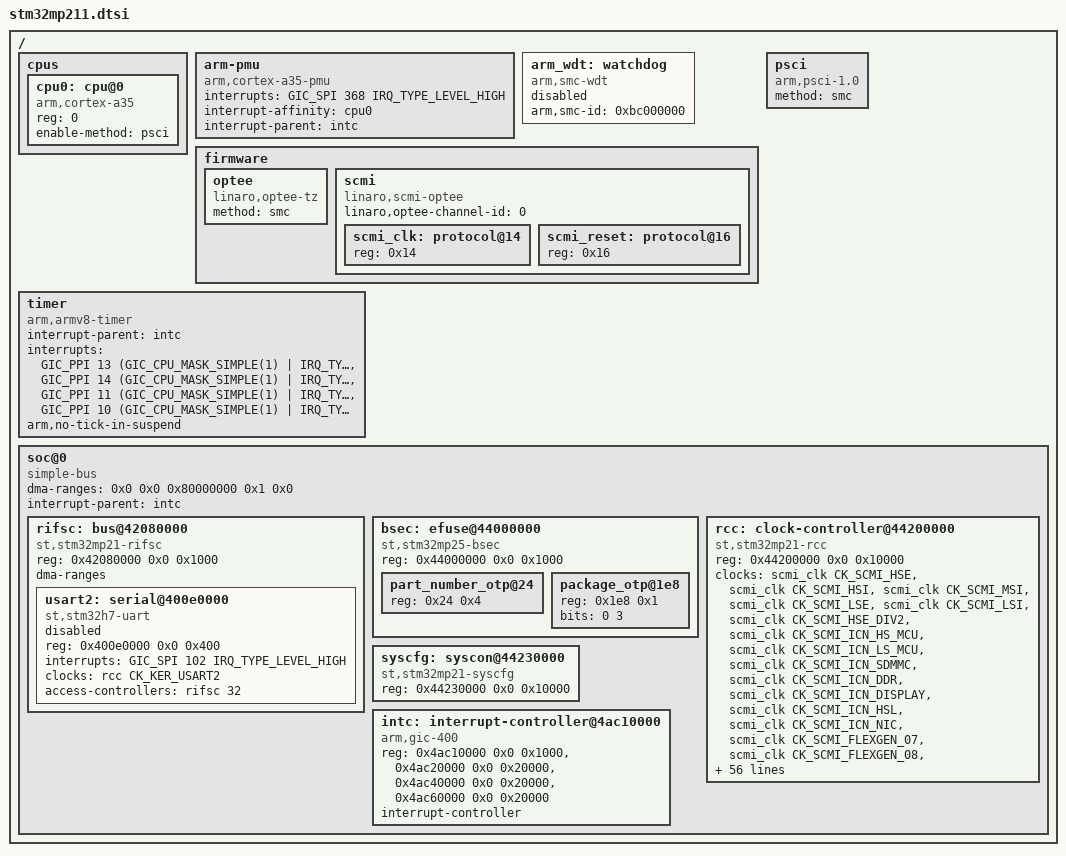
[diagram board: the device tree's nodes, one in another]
// SPDX-License-Identifier: (GPL-2.0-only OR BSD-3-Clause)
/*
 * Copyright (C) STMicroelectronics 2025 - All Rights Reserved
 * Author: Alexandre Torgue <alexandre.torgue@foss.st.com> for STMicroelectronics.
 */
#include <dt-bindings/clock/st,stm32mp21-rcc.h>
#include <dt-bindings/interrupt-controller/arm-gic.h>
#include <dt-bindings/reset/st,stm32mp21-rcc.h>

/ {
	#address-cells = <2>;
	#size-cells = <2>;

	cpus {
		#address-cells = <1>;
		#size-cells = <0>;

		cpu0: cpu@0 {
			compatible = "arm,cortex-a35";
			reg = <0>;
			device_type = "cpu";
			enable-method = "psci";
		};
	};

	arm-pmu {
		compatible = "arm,cortex-a35-pmu";
		interrupts = <GIC_SPI 368 IRQ_TYPE_LEVEL_HIGH>;
		interrupt-affinity = <&cpu0>;
		interrupt-parent = <&intc>;
	};

	arm_wdt: watchdog {
		compatible = "arm,smc-wdt";
		arm,smc-id = <0xbc000000>;
		status = "disabled";
	};

	firmware {
		optee {
			compatible = "linaro,optee-tz";
			method = "smc";
		};

		scmi: scmi {
			compatible = "linaro,scmi-optee";
			#address-cells = <1>;
			#size-cells = <0>;
			linaro,optee-channel-id = <0>;

			scmi_clk: protocol@14 {
				reg = <0x14>;
				#clock-cells = <1>;
			};

			scmi_reset: protocol@16 {
				reg = <0x16>;
				#reset-cells = <1>;
			};
		};
	};

	psci {
		compatible = "arm,psci-1.0";
		method = "smc";
	};

	timer {
		compatible = "arm,armv8-timer";
		interrupt-parent = <&intc>;
		interrupts = <GIC_PPI 13 (GIC_CPU_MASK_SIMPLE(1) | IRQ_TYPE_LEVEL_LOW)>,
			     <GIC_PPI 14 (GIC_CPU_MASK_SIMPLE(1) | IRQ_TYPE_LEVEL_LOW)>,
			     <GIC_PPI 11 (GIC_CPU_MASK_SIMPLE(1) | IRQ_TYPE_LEVEL_LOW)>,
			     <GIC_PPI 10 (GIC_CPU_MASK_SIMPLE(1) | IRQ_TYPE_LEVEL_LOW)>;
		arm,no-tick-in-suspend;
	};

	soc@0 {
		compatible = "simple-bus";
		ranges = <0x0 0x0 0x0 0x0 0x80000000>;
		dma-ranges = <0x0 0x0 0x80000000 0x1 0x0>;
		interrupt-parent = <&intc>;
		#address-cells = <1>;
		#size-cells = <2>;

		rifsc: bus@42080000 {
			compatible = "st,stm32mp21-rifsc", "simple-bus";
			reg = <0x42080000 0x0 0x1000>;
			ranges;
			dma-ranges;
			#address-cells = <1>;
			#size-cells = <2>;
			#access-controller-cells = <1>;

			usart2: serial@400e0000 {
				compatible = "st,stm32h7-uart";
				reg = <0x400e0000 0x0 0x400>;
				interrupts = <GIC_SPI 102 IRQ_TYPE_LEVEL_HIGH>;
				clocks = <&rcc CK_KER_USART2>;
				access-controllers = <&rifsc 32>;
				status = "disabled";
			};
		};

		bsec: efuse@44000000 {
			compatible = "st,stm32mp25-bsec";
			reg = <0x44000000 0x0 0x1000>;
			#address-cells = <1>;
			#size-cells = <1>;

			part_number_otp@24 {
				reg = <0x24 0x4>;
			};

			package_otp@1e8 {
				reg = <0x1e8 0x1>;
				bits = <0 3>;
			};
		};

		rcc: clock-controller@44200000 {
			compatible = "st,stm32mp21-rcc";
			reg = <0x44200000 0x0 0x10000>;
			#clock-cells = <1>;
			#reset-cells = <1>;
			clocks =
				<&scmi_clk CK_SCMI_HSE>,
				<&scmi_clk CK_SCMI_HSI>,
				<&scmi_clk CK_SCMI_MSI>,
				<&scmi_clk CK_SCMI_LSE>,
				<&scmi_clk CK_SCMI_LSI>,
				<&scmi_clk CK_SCMI_HSE_DIV2>,
				<&scmi_clk CK_SCMI_ICN_HS_MCU>,
				<&scmi_clk CK_SCMI_ICN_LS_MCU>,
				<&scmi_clk CK_SCMI_ICN_SDMMC>,
				<&scmi_clk CK_SCMI_ICN_DDR>,
				<&scmi_clk CK_SCMI_ICN_DISPLAY>,
				<&scmi_clk CK_SCMI_ICN_HSL>,
				<&scmi_clk CK_SCMI_ICN_NIC>,
				<&scmi_clk CK_SCMI_FLEXGEN_07>,
				<&scmi_clk CK_SCMI_FLEXGEN_08>,
				<&scmi_clk CK_SCMI_FLEXGEN_09>,
				<&scmi_clk CK_SCMI_FLEXGEN_10>,
				<&scmi_clk CK_SCMI_FLEXGEN_11>,
				<&scmi_clk CK_SCMI_FLEXGEN_12>,
				<&scmi_clk CK_SCMI_FLEXGEN_13>,
				<&scmi_clk CK_SCMI_FLEXGEN_14>,
				<&scmi_clk CK_SCMI_FLEXGEN_16>,
				<&scmi_clk CK_SCMI_FLEXGEN_17>,
				<&scmi_clk CK_SCMI_FLEXGEN_18>,
				<&scmi_clk CK_SCMI_FLEXGEN_19>,
				<&scmi_clk CK_SCMI_FLEXGEN_20>,
				<&scmi_clk CK_SCMI_FLEXGEN_21>,
				<&scmi_clk CK_SCMI_FLEXGEN_22>,
				<&scmi_clk CK_SCMI_FLEXGEN_23>,
				<&scmi_clk CK_SCMI_FLEXGEN_24>,
				<&scmi_clk CK_SCMI_FLEXGEN_25>,
				<&scmi_clk CK_SCMI_FLEXGEN_26>,
				<&scmi_clk CK_SCMI_FLEXGEN_27>,
				<&scmi_clk CK_SCMI_FLEXGEN_29>,
				<&scmi_clk CK_SCMI_FLEXGEN_30>,
				<&scmi_clk CK_SCMI_FLEXGEN_31>,
				<&scmi_clk CK_SCMI_FLEXGEN_33>,
				<&scmi_clk CK_SCMI_FLEXGEN_36>,
				<&scmi_clk CK_SCMI_FLEXGEN_37>,
				<&scmi_clk CK_SCMI_FLEXGEN_38>,
				<&scmi_clk CK_SCMI_FLEXGEN_39>,
				<&scmi_clk CK_SCMI_FLEXGEN_40>,
				<&scmi_clk CK_SCMI_FLEXGEN_41>,
				<&scmi_clk CK_SCMI_FLEXGEN_42>,
				<&scmi_clk CK_SCMI_FLEXGEN_43>,
				<&scmi_clk CK_SCMI_FLEXGEN_44>,
				<&scmi_clk CK_SCMI_FLEXGEN_45>,
				<&scmi_clk CK_SCMI_FLEXGEN_46>,
				<&scmi_clk CK_SCMI_FLEXGEN_47>,
				<&scmi_clk CK_SCMI_FLEXGEN_48>,
				<&scmi_clk CK_SCMI_FLEXGEN_50>,
				<&scmi_clk CK_SCMI_FLEXGEN_51>,
				<&scmi_clk CK_SCMI_FLEXGEN_52>,
				<&scmi_clk CK_SCMI_FLEXGEN_53>,
				<&scmi_clk CK_SCMI_FLEXGEN_54>,
				<&scmi_clk CK_SCMI_FLEXGEN_55>,
				<&scmi_clk CK_SCMI_FLEXGEN_56>,
				<&scmi_clk CK_SCMI_FLEXGEN_57>,
				<&scmi_clk CK_SCMI_FLEXGEN_58>,
				<&scmi_clk CK_SCMI_FLEXGEN_61>,
				<&scmi_clk CK_SCMI_FLEXGEN_62>,
				<&scmi_clk CK_SCMI_FLEXGEN_63>,
				<&scmi_clk CK_SCMI_ICN_APB1>,
				<&scmi_clk CK_SCMI_ICN_APB2>,
				<&scmi_clk CK_SCMI_ICN_APB3>,
				<&scmi_clk CK_SCMI_ICN_APB4>,
				<&scmi_clk CK_SCMI_ICN_APB5>,
				<&scmi_clk CK_SCMI_ICN_APBDBG>,
				<&scmi_clk CK_SCMI_TIMG1>,
				<&scmi_clk CK_SCMI_TIMG2>;
			access-controllers = <&rifsc 156>;
		};

		syscfg: syscon@44230000 {
			compatible = "st,stm32mp21-syscfg", "syscon";
			reg = <0x44230000 0x0 0x10000>;
		};

		intc: interrupt-controller@4ac10000 {
			compatible = "arm,gic-400";
			reg = <0x4ac10000 0x0 0x1000>,
			      <0x4ac20000 0x0 0x20000>,
			      <0x4ac40000 0x0 0x20000>,
			      <0x4ac60000 0x0 0x20000>;
			      #interrupt-cells = <3>;
			      interrupt-controller;
		};
	};
};
